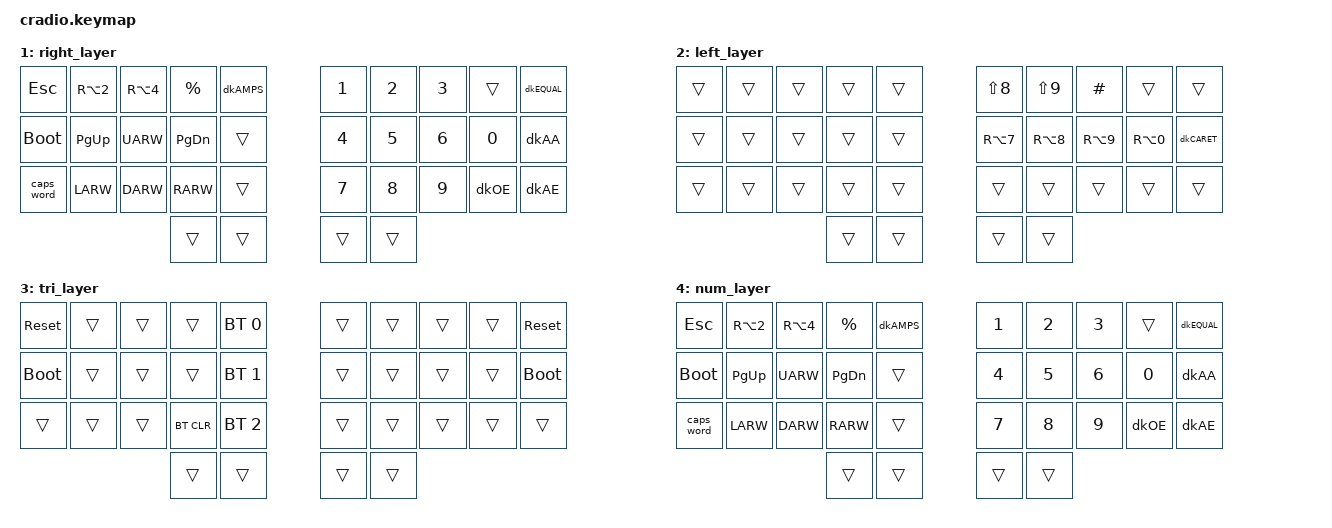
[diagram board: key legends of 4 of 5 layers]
// Copyright (c) 2022 The ZMK Contributors
// SPDX-License-Identifier: MIT

#include <behaviors.dtsi>
#include <dt-bindings/zmk/keys.h>
#include <dt-bindings/zmk/bt.h>

// Home row mods macro
#define HRML(k1,k2,k3) &ht LSHFT k1 &ht LCTRL k2 &ht LALT k3 
#define HRMR(k1,k2,k3) &ht RALT k1 &ht RCTRL k2  &ht RSHFT k3

// Mapping US to DK
#define dkAA LBKT
#define dkAE SEMI
#define dkOE SQT
#define dkAMPS CARET
#define dkRPAR LPAR
#define dkLPAR ASTRK
#define dkEQUAL RPAR
#define dkCARET RBKT

/ {
    behaviors {
        ht: hold_tap {
            label = "hold_tap";
            compatible = "zmk,behavior-hold-tap";
            #binding-cells = <2>;
            flavor = "tap-preferred";
            tapping-term-ms = <220>;
            quick-tap-ms = <150>;
            global-quick-tap;
            bindings = <&kp>, <&kp>;
        };
    };

    conditional_layers {
        compatible = "zmk,conditional-layers";
        tri_layer {
            if-layers = <1 2>;
            then-layer = <3>;
        };
    };

    keymap {
        compatible = "zmk,keymap";
        default_layer {
            bindings = <
        //╭──────────┬──────────┬──────────┬──────────┬──────────╮   ╭──────────┬──────────┬──────────┬──────────┬──────────╮
            &kp Q      &kp W      &kp E      &kp R      &kp T          &kp Y      &kp U      &kp I      &kp O      &kp P
        //├──────────┼──────────┼──────────┼──────────┼──────────┤   ├──────────┼──────────┼──────────┼──────────┼──────────┤
            HRML(A,        S,         D)     &lt 2 F   &kp G          &lt 4 H    &lt 1 J    HRMR( K,         L,        RGUI)
        //├──────────┼──────────┼──────────┼──────────┼──────────┤   ├──────────┼──────────┼──────────┼──────────┼──────────┤
            &kp Z      &kp X      &kp C      &kp V      &kp B          &kp N      &kp M      &kp COMMA  &kp DOT    &kp FSLH
        //╰──────────┴──────────┴──────────┼──────────┼──────────┤   ├──────────┼──────────┼──────────┴──────────┴──────────╯
                                            &ht LCTRL TAB &lt 4 ENTER  &lt 2 SPACE &kp BSPC
        //                                 ╰──────────┴──────────╯   ╰──────────┴──────────╯
            >;
        };
        
        right_layer {
            bindings = <
        //│  Esc     │ @        │  $       │  %       │ &        │    ╭──────────┬──────────┬──────────┬──────────┬──────────╮
            &kp ESC   &kp RA(N2)   &kp RA(N4)  &kp PRCNT &kp dkAMPS     &kp N1    &kp N2     &kp N3     &trans     &kp dkEQUAL
        //├──────────┼──────────┼──────────┼──────────┼──────────┤   ├──────────┼──────────┼──────────┼──────────┼──────────┤
          &bootloader  &kp PG_UP   &kp UARW  &kp PG_DN   &trans          &kp N4    &kp N5     &kp N6     &kp N0     &kp dkAA
        //├──────────┼──────────┼──────────┼──────────┼──────────┤   ├──────────┼──────────┼──────────┼──────────┼──────────┤
           &caps_word   &kp LARW    &kp DARW   &kp RARW   &trans          &kp N7    &kp N8     &kp N9     &kp dkOE   &kp dkAE 
        //╰──────────┴──────────┴──────────┼──────────┼──────────┤   ├──────────┼──────────┼──────────┴──────────┴──────────╯
                                             &trans    &trans        &trans     &trans
        //                                 ╰──────────┴──────────╯   ╰──────────┴──────────╯
            >;
        };
        left_layer {
            bindings = <
        //╭──────────┬──────────┬──────────┬──────────┬──────────╮   ╭──────────┬──────────┬──────────┬──────────┬──────────╮
        //│          │          │          │          │          │   │  (       │  )       │ #        │          │
           &trans     &trans     &trans     &trans     &trans        &kp LS(N8) &kp LS(N9) &kp HASH     &trans     &trans    
        //├──────────┼──────────┼──────────┼──────────┼──────────┤   ├──────────┼──────────┼──────────┼──────────┼──────────┤
        //│          │          │          │          │          │   │  {       │  [      │  ]        │  }      │  ¨^~     │  
            &trans     &trans     &trans     &trans     &trans       &kp RA(N7) &kp RA(N8) &kp RA(N9) &kp RA(N0) &kp dkCARET 
        //├──────────┼──────────┼──────────┼──────────┼──────────┤   ├──────────┼──────────┼──────────┼──────────┼──────────┤   
           &trans     &trans     &trans      &trans     &trans          &trans     &trans     &trans     &trans     &trans    
        //╰──────────┴──────────┴──────────┼──────────┼──────────┤   ├──────────┼──────────┼──────────┴──────────┴──────────╯
                                             &trans   &trans          &trans     &trans
        //                                 ╰──────────┴──────────╯   ╰──────────┴──────────╯
            >;
        };

        tri_layer {
            bindings = <
        //╭──────────┬──────────┬──────────┬──────────┬──────────╮   ╭──────────┬──────────┬──────────┬──────────┬──────────╮
        //│ RESET    │          │          │          │PROFILE 0 │   │          │          │          │          │  RESET   │
           &sys_reset  &trans     &trans     &trans    &bt BT_SEL 0    &trans     &trans     &trans     &trans    &sys_reset
        //├──────────┼──────────┼──────────┼──────────┼──────────┤   ├──────────┼──────────┼──────────┼──────────┼──────────┤
        //│BOOTLOADER│          │          │          │PROFILE 1 │   │          │          │          │          │BOOTLOADER│
          &bootloader  &trans     &trans     &trans    &bt BT_SEL 1    &trans     &trans     &trans     &trans    &bootloader
        //├──────────┼──────────┼──────────┼──────────┼──────────┤   ├──────────┼──────────┼──────────┼──────────┼──────────┤
        //│          │          │          │ CLEAR BT │PROFILE 2 │   │          │          │          │          │          │
            &trans     &trans     &trans    &bt BT_CLR &bt BT_SEL 2    &trans     &trans     &trans     &trans     &trans
        //╰──────────┴──────────┴──────────┼──────────┼──────────┤   ├──────────┼──────────┼──────────┴──────────┴──────────╯
                                             &trans     &trans         &trans     &trans
        //                                 ╰──────────┴──────────╯   ╰──────────┴──────────╯
            >;
        };


       num_layer {
            bindings = <
        //│  Esc     │ @        │  $       │  %       │ &        │    ╭──────────┬──────────┬──────────┬──────────┬──────────╮
            &kp ESC   &kp RA(N2)   &kp RA(N4)  &kp PRCNT &kp dkAMPS     &kp N1    &kp N2     &kp N3     &trans     &kp dkEQUAL
        //├──────────┼──────────┼──────────┼──────────┼──────────┤   ├──────────┼──────────┼──────────┼──────────┼──────────┤
          &bootloader  &kp PG_UP   &kp UARW  &kp PG_DN   &trans          &kp N4    &kp N5     &kp N6     &kp N0     &kp dkAA
        //├──────────┼──────────┼──────────┼──────────┼──────────┤   ├──────────┼──────────┼──────────┼──────────┼──────────┤
           &caps_word   &kp LARW    &kp DARW   &kp RARW   &trans          &kp N7    &kp N8     &kp N9     &kp dkOE   &kp dkAE 
        //╰──────────┴──────────┴──────────┼──────────┼──────────┤   ├──────────┼──────────┼──────────┴──────────┴──────────╯
                                             &trans    &trans        &trans     &trans
        //                                 ╰──────────┴──────────╯   ╰──────────┴──────────╯
            >;
        };
    };
};
